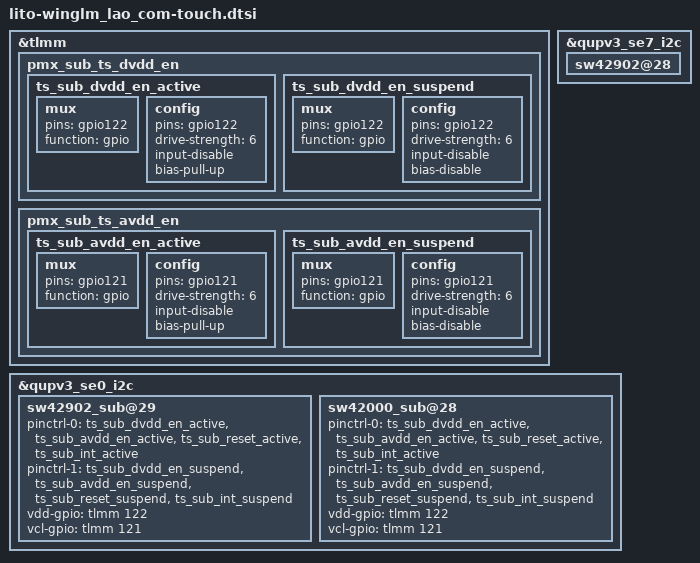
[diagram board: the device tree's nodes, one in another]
// SPDX-License-Identifier: GPL-2.0-only
/*
 * Copyright (c) 2018-2019, The Linux Foundation. All rights reserved.
 */

#include "../lito-winglm_common/lito-winglm_common-touch.dtsi"

&tlmm {
	pmx_sub_ts_dvdd_en {
		ts_sub_dvdd_en_active: ts_sub_dvdd_en_active {
			mux {
				pins = "gpio122";
				function = "gpio";
			};
			config {
				pins = "gpio122";
				drive-strength = <6>;
				input-disable;
				bias-pull-up;
			};
		};

		ts_sub_dvdd_en_suspend: ts_sub_dvdd_en_suspend {
			mux {
				pins = "gpio122";
				function = "gpio";
			};
			config {
				pins = "gpio122";
				drive-strength = <6>;
				input-disable;
				bias-disable;
			};
		};
	};

	pmx_sub_ts_avdd_en {
		ts_sub_avdd_en_active: ts_sub_avdd_en_active {
			mux {
				pins = "gpio121";
				function = "gpio";
			};
			config {
				pins = "gpio121";
				drive-strength = <6>;
				input-disable;
				bias-pull-up;
			};
		};

		ts_sub_avdd_en_suspend: ts_sub_avdd_en_suspend {
			mux {
				pins = "gpio121";
				function = "gpio";
			};
			config {
				pins = "gpio121";
				drive-strength = <6>;
				input-disable;
				bias-disable;
			};
                };
	};
};

&qupv3_se7_i2c {
	#address-cells = <1>;
	#size-cells = <0>;

	status = "ok";

	sw42902@28 {
		status = "ok";

	};
};

&qupv3_se0_i2c {
	#address-cells = <1>;
	#size-cells = <0>;

	status = "ok";

	sw42902_sub@29 {
		status = "ok";

		pinctrl-names = "touch_sub_pin_active", "touch_sub_pin_sleep";
		pinctrl-0 = <&ts_sub_dvdd_en_active &ts_sub_avdd_en_active &ts_sub_reset_active &ts_sub_int_active>;
		pinctrl-1 = <&ts_sub_dvdd_en_suspend &ts_sub_avdd_en_suspend &ts_sub_reset_suspend &ts_sub_int_suspend>;

		vdd-gpio = <&tlmm 122 0x00>;
		vcl-gpio = <&tlmm 121 0x00>;
	};
	sw42000_sub@28 {
		status = "ok";

		pinctrl-names = "touch_sub_pin_active", "touch_sub_pin_sleep";
		pinctrl-0 = <&ts_sub_dvdd_en_active &ts_sub_avdd_en_active &ts_sub_reset_active &ts_sub_int_active>;
		pinctrl-1 = <&ts_sub_dvdd_en_suspend &ts_sub_avdd_en_suspend &ts_sub_reset_suspend &ts_sub_int_suspend>;

		vdd-gpio = <&tlmm 122 0x00>;
		vcl-gpio = <&tlmm 121 0x00>;
	};
};

